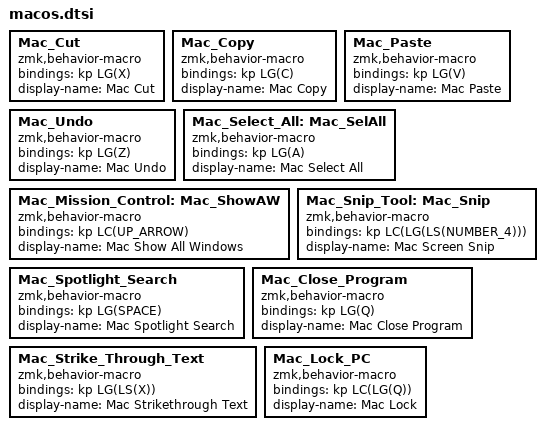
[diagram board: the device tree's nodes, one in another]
// ═══════════════════════════════════════════════════════════════
// MacOS macros
// Version: 0.1
// Date: 05/Oct/2026
// ═══════════════════════════════════════════════════════════════

Mac_Cut: Mac_Cut {
    compatible = "zmk,behavior-macro";
    #binding-cells = <0>;
    bindings = <&kp LG(X)>;
    display-name = "Mac Cut";
};

Mac_Copy: Mac_Copy {
    compatible = "zmk,behavior-macro";
    #binding-cells = <0>;
    bindings = <&kp LG(C)>;
    display-name = "Mac Copy";
};

Mac_Paste: Mac_Paste {
    compatible = "zmk,behavior-macro";
    #binding-cells = <0>;
    bindings = <&kp LG(V)>;
    display-name = "Mac Paste";
};

Mac_Undo: Mac_Undo {
    compatible = "zmk,behavior-macro";
    #binding-cells = <0>;
    bindings = <&kp LG(Z)>;
    display-name = "Mac Undo";
};

Mac_Select_All: Mac_SelAll {
    compatible = "zmk,behavior-macro";
    #binding-cells = <0>;
    bindings = <&kp LG(A)>;
    display-name = "Mac Select All";
};

Mac_Mission_Control: Mac_ShowAW {
    compatible = "zmk,behavior-macro";
    #binding-cells = <0>;
    bindings = <&kp LC(UP_ARROW)>;
    display-name = "Mac Show All Windows";
};

Mac_Snip_Tool: Mac_Snip {
    compatible = "zmk,behavior-macro";
    #binding-cells = <0>;
    bindings = <&kp LC(LG(LS(NUMBER_4)))>;
    display-name = "Mac Screen Snip";
};

Mac_Spotlight_Search: Mac_Spotlight_Search {
    compatible = "zmk,behavior-macro";
    #binding-cells = <0>;
    bindings = <&kp LG(SPACE)>;
    display-name = "Mac Spotlight Search";
};

Mac_Close_Program: Mac_Close_Program {
    compatible = "zmk,behavior-macro";
    #binding-cells = <0>;
    bindings = <&kp LG(Q)>;
    display-name = "Mac Close Program";
};

Mac_Strike_Through_Text: Mac_Strike_Through_Text {
    compatible = "zmk,behavior-macro";
    #binding-cells = <0>;
    bindings = <&kp LG(LS(X))>;
    display-name = "Mac Strikethrough Text";
};

Mac_Lock_PC: Mac_Lock_PC {
    compatible = "zmk,behavior-macro";
    #binding-cells = <0>;
    bindings = <&kp LC(LG(Q))>;
    display-name = "Mac Lock";
};
